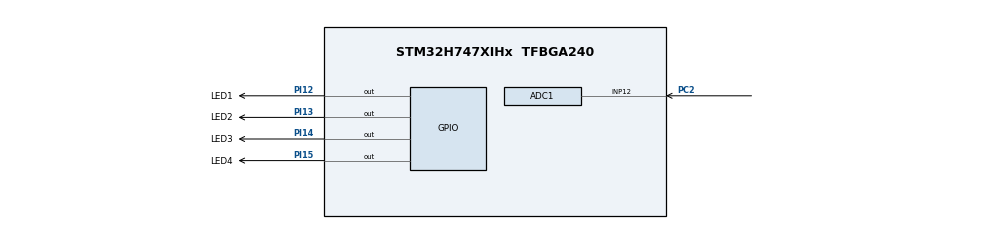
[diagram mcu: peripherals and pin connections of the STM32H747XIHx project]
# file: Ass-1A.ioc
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ADC1.Channel-1\#ChannelRegularConversion=ADC_CHANNEL_12
ADC1.ConversionDataManagement=ADC_CONVERSIONDATA_DMA_CIRCULAR
ADC1.ExternalTrigConv=ADC_EXTERNALTRIG_T3_TRGO
ADC1.NbrOfConversionFlag=1
ADC1.OffsetNumber-1\#ChannelRegularConversion=ADC_OFFSET_NONE
ADC1.OffsetSignedSaturation-1\#ChannelRegularConversion=DISABLE
ADC1.Overrun=ADC_OVR_DATA_OVERWRITTEN
ADC1.Rank-1\#ChannelRegularConversion=1
ADC1.Resolution=ADC_RESOLUTION_12B
ADC1.SamplingTime-1\#ChannelRegularConversion=ADC_SAMPLETIME_1CYCLE_5
ADC1.master=1
CortexM4.IPs=BDMA,DMA,FATFS_M4\:I,FREERTOS_M4\:I,IWDG2\:I,MDMA,NVIC2\:I,RCC,USB_DEVICE_M4\:I,USB_HOST_M4\:I,WWDG2\:I,USART1,USB_OTG_HS\:I,SPI2\:I,ADC3\:I,FMC\:I,QUADSPI\:I,SAI1\:I,ETH\:I,SPI5\:I,TIM8\:I,UART8\:I,DCMI\:I,RTC\:I,SDMMC1\:I,SPDIFRX1\:I,HDMI_CEC\:I,TIM13\:I,DEBUG,PDM2PCM_M4\:I,PWR,RESMGR_UTILITY,SYS_M4\:I,CORTEX_M4\:I,OPENAMP_M4\:I,VREFBUF,GPIO
CortexM7.IPs=BDMA\:I,DMA\:I,FATFS_M7\:I,FREERTOS_M7\:I,IWDG1\:I,MDMA\:I,NVIC1\:I,RCC\:I,USB_DEVICE_M7\:I,USB_HOST_M7\:I,WWDG1\:I,USART1\:I,CORTEX_M7\:I,DEBUG\:I,PDM2PCM_M7\:I,PWR\:I,RESMGR_UTILITY\:I,SYS\:I,OPENAMP_M7\:I,VREFBUF\:I,GPIO\:I,MEMORYMAP\:I,TIM3\:I,ADC1\:I
CortexM7.Pins=PI12,PI13,PI14,PI15
Dma.ADC1.0.Direction=DMA_PERIPH_TO_MEMORY
Dma.ADC1.0.EventEnable=DISABLE
Dma.ADC1.0.FIFOMode=DMA_FIFOMODE_DISABLE
Dma.ADC1.0.Instance=DMA1_Stream0
Dma.ADC1.0.MemDataAlignment=DMA_MDATAALIGN_HALFWORD
Dma.ADC1.0.MemInc=DMA_MINC_ENABLE
Dma.ADC1.0.Mode=DMA_CIRCULAR
Dma.ADC1.0.PeriphDataAlignment=DMA_PDATAALIGN_HALFWORD
Dma.ADC1.0.PeriphInc=DMA_PINC_DISABLE
Dma.ADC1.0.Polarity=HAL_DMAMUX_REQ_GEN_RISING
Dma.ADC1.0.Priority=DMA_PRIORITY_LOW
Dma.ADC1.0.RequestNumber=1
Dma.ADC1.0.SignalID=NONE
Dma.ADC1.0.SyncEnable=DISABLE
Dma.ADC1.0.SyncPolarity=HAL_DMAMUX_SYNC_NO_EVENT
Dma.ADC1.0.SyncRequestNumber=1
Dma.ADC1.0.SyncSignalID=NONE
Dma.Request0=ADC1
Mcu.Family=STM32H7
Mcu.Name=STM32H747XIHx
Mcu.Package=TFBGA240
NVIC1.ADC_IRQn=true\:0\:0\:false\:false\:true\:true\:true\:true
NVIC1.DMA1_Stream0_IRQn=true\:0\:0\:false\:false\:true\:false\:true\:true
NVIC1.PriorityGroup=NVIC_PRIORITYGROUP_4
NVIC1.TIM3_IRQn=true\:0\:0\:false\:false\:true\:true\:true\:true
NVIC2.PriorityGroup=NVIC_PRIORITYGROUP_4
PC2.PinAttribute=CortexM7
PC2.Signal=ADCx_INP12
PH0-OSC_IN\ (PH0).Mode=HSE-External-Oscillator
PH0-OSC_IN\ (PH0).PinAttribute=Free
PH0-OSC_IN\ (PH0).Signal=RCC_OSC_IN
PH1-OSC_OUT\ (PH1).Mode=HSE-External-Oscillator
PH1-OSC_OUT\ (PH1).PinAttribute=Free
PH1-OSC_OUT\ (PH1).Signal=RCC_OSC_OUT
PI12.GPIO_Label=LED1
PI12.PinAttribute=CortexM7
PI12.Signal=GPIO_Output
PI13.GPIO_Label=LED2
PI13.PinAttribute=CortexM7
PI13.Signal=GPIO_Output
PI14.GPIO_Label=LED3
PI14.PinAttribute=CortexM7
PI14.Signal=GPIO_Output
PI15.GPIO_Label=LED4
PI15.PinAttribute=CortexM7
PI15.Signal=GPIO_Output
ProjectManager.HeapSize=M4-0x200,M7-0x200
ProjectManager.StackSize=M4-0x400,M7-0x400
ProjectManager.TargetToolchain=STM32CubeIDE
RCC.ADCFreq_Value=75000000
RCC.APB1Freq_Value=100000000
RCC.APB2Freq_Value=100000000
RCC.APB3Freq_Value=100000000
RCC.APB4Freq_Value=100000000
RCC.CortexFreq_Value=400000000
RCC.D1PPRE=RCC_APB3_DIV2
RCC.D2PPRE1=RCC_APB1_DIV2
RCC.D2PPRE2=RCC_APB2_DIV2
RCC.D3PPRE=RCC_APB4_DIV2
RCC.DIVM1=5
RCC.DIVM2=2
RCC.DIVN1=160
RCC.DIVN2=12
RCC.DIVQ1=5
RCC.HCLKFreq_Value=200000000
RCC.HPRE=RCC_HCLK_DIV2
RCC.PLL2FRACN=0
RCC.PLL3FRACN=0
RCC.PLLFRACN=0
RCC.PLLSourceVirtual=RCC_PLLSOURCE_HSE
RCC.PWR_Regulator_Voltage_Scale=PWR_REGULATOR_VOLTAGE_SCALE1
RCC.SYSCLKFreq_VALUE=400000000
RCC.SYSCLKSource=RCC_SYSCLKSOURCE_PLLCLK
RCC.SupplySource=PWR_DIRECT_SMPS_SUPPLY
RCC.USBFreq_Value=160000000
SH.ADCx_INP12.0=ADC1_INP12,IN12-Single-Ended
TIM3.AutoReloadPreload=TIM_AUTORELOAD_PRELOAD_DISABLE
TIM3.Period=4999
TIM3.Prescaler=9999
TIM3.TIM_MasterOutputTrigger=TIM_TRGO_UPDATE
VP_MEMORYMAP_VS_MEMORYMAP.Mode=CurAppReg
VP_SYS_M4_VS_Systick.Mode=SysTick
VP_TIM3_VS_ClockSourceINT.Mode=Internal
board=STM32H747I-DISCO

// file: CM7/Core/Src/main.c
/* USER CODE BEGIN Header */
/**
  ******************************************************************************
  * @file           : main.c
  * @brief          : Main program body
  ******************************************************************************
  * @attention
  *
  * Copyright (c) 2025 STMicroelectronics.
  * All rights reserved.
  *
  * This software is licensed under terms that can be found in the LICENSE file
  * in the root directory of this software component.
  * If no LICENSE file comes with this software, it is provided AS-IS.
  *
  ******************************************************************************
  */
/* USER CODE END Header */
#include "main.h"

/* USER CODE BEGIN Includes */
#include "Ass-1A.h"
/* USER CODE END Includes */

/* USER CODE BEGIN PD */

#ifndef HSEM_ID_0
#define HSEM_ID_0 (0U) /* HW semaphore 0*/
#endif

/* USER CODE END PD */

ADC_HandleTypeDef hadc1;
DMA_HandleTypeDef hdma_adc1;

TIM_HandleTypeDef htim3;

void SystemClock_Config(void);
static void MX_GPIO_Init(void);
static void MX_DMA_Init(void);
static void MX_TIM3_Init(void);
static void MX_ADC1_Init(void);
/* USER CODE BEGIN PFP */
extern void initialise_monitor_handles(void);
/* USER CODE END PFP */

int main(void)
{

  /* USER CODE BEGIN 1 */
 	initialise_monitor_handles();
  /* USER CODE END 1 */
/* USER CODE BEGIN Boot_Mode_Sequence_0 */
//  int32_t timeout;
/* USER CODE END Boot_Mode_Sequence_0 */

/* USER CODE BEGIN Boot_Mode_Sequence_1 */
  /* Wait until CPU2 boots and enters in stop mode or timeout*/
/*
	timeout = 0xFFFF;
  while((__HAL_RCC_GET_FLAG(RCC_FLAG_D2CKRDY) != RESET) && (timeout-- > 0));
  if ( timeout < 0 )
  {
  Error_Handler();
  }
 */
/* USER CODE END Boot_Mode_Sequence_1 */
  /* MCU Configuration--------------------------------------------------------*/

  /* Reset of all peripherals, Initializes the Flash interface and the Systick. */
  HAL_Init();

  /* Configure the system clock */
  SystemClock_Config();
/* USER CODE BEGIN Boot_Mode_Sequence_2 */
/* When system initialization is finished, Cortex-M7 will release Cortex-M4 by means of
HSEM notification */
/*HW semaphore Clock enable*/
//__HAL_RCC_HSEM_CLK_ENABLE();
/*Take HSEM */
//HAL_HSEM_FastTake(HSEM_ID_0);
/*Release HSEM in order to notify the CPU2(CM4)*/
//HAL_HSEM_Release(HSEM_ID_0,0);
/* wait until CPU2 wakes up from stop mode */
//timeout = 0xFFFF;
//while((__HAL_RCC_GET_FLAG(RCC_FLAG_D2CKRDY) == RESET) && (timeout-- > 0));
//if ( timeout < 0 )
//{
//Error_Handler();
//}
/* USER CODE END Boot_Mode_Sequence_2 */

  /* Initialize all configured peripherals */
  MX_GPIO_Init();
  MX_DMA_Init();
  MX_TIM3_Init();
  MX_ADC1_Init();
  /* USER CODE BEGIN 2 */
  // Start with LED off
	HAL_GPIO_WritePin (GPIOI, LED1_Pin,1);
	HAL_GPIO_WritePin (GPIOI, LED2_Pin,1);
	HAL_GPIO_WritePin (GPIOI, LED3_Pin,1);
	HAL_GPIO_WritePin (GPIOI, LED4_Pin,1);

  // Call the user code (never returns)
  Ass_1A_main();

  /* USER CODE END 2 */

  /* Infinite loop */
  while (1)
  {

  }
}

void SystemClock_Config(void)
{
  RCC_OscInitTypeDef RCC_OscInitStruct = {0};
  RCC_ClkInitTypeDef RCC_ClkInitStruct = {0};

  /** Supply configuration update enable
  */
  HAL_PWREx_ConfigSupply(PWR_DIRECT_SMPS_SUPPLY);

  /** Configure the main internal regulator output voltage
  */
  __HAL_PWR_VOLTAGESCALING_CONFIG(PWR_REGULATOR_VOLTAGE_SCALE1);

  while(!__HAL_PWR_GET_FLAG(PWR_FLAG_VOSRDY)) {}

  /** Initializes the RCC Oscillators according to the specified parameters
  * in the RCC_OscInitTypeDef structure.
  */
  RCC_OscInitStruct.OscillatorType = RCC_OSCILLATORTYPE_HSE;
  RCC_OscInitStruct.HSEState = RCC_HSE_ON;
  RCC_OscInitStruct.PLL.PLLState = RCC_PLL_ON;
  RCC_OscInitStruct.PLL.PLLSource = RCC_PLLSOURCE_HSE;
  RCC_OscInitStruct.PLL.PLLM = 5;
  RCC_OscInitStruct.PLL.PLLN = 160;
  RCC_OscInitStruct.PLL.PLLP = 2;
  RCC_OscInitStruct.PLL.PLLQ = 5;
  RCC_OscInitStruct.PLL.PLLR = 2;
  RCC_OscInitStruct.PLL.PLLRGE = RCC_PLL1VCIRANGE_2;
  RCC_OscInitStruct.PLL.PLLVCOSEL = RCC_PLL1VCOWIDE;
  RCC_OscInitStruct.PLL.PLLFRACN = 0;
  if (HAL_RCC_OscConfig(&RCC_OscInitStruct) != HAL_OK)
  {
    Error_Handler();
  }

  /** Initializes the CPU, AHB and APB buses clocks
  */
  RCC_ClkInitStruct.ClockType = RCC_CLOCKTYPE_HCLK|RCC_CLOCKTYPE_SYSCLK
                              |RCC_CLOCKTYPE_PCLK1|RCC_CLOCKTYPE_PCLK2
                              |RCC_CLOCKTYPE_D3PCLK1|RCC_CLOCKTYPE_D1PCLK1;
  RCC_ClkInitStruct.SYSCLKSource = RCC_SYSCLKSOURCE_PLLCLK;
  RCC_ClkInitStruct.SYSCLKDivider = RCC_SYSCLK_DIV1;
  RCC_ClkInitStruct.AHBCLKDivider = RCC_HCLK_DIV2;
  RCC_ClkInitStruct.APB3CLKDivider = RCC_APB3_DIV2;
  RCC_ClkInitStruct.APB1CLKDivider = RCC_APB1_DIV2;
  RCC_ClkInitStruct.APB2CLKDivider = RCC_APB2_DIV2;
  RCC_ClkInitStruct.APB4CLKDivider = RCC_APB4_DIV2;

  if (HAL_RCC_ClockConfig(&RCC_ClkInitStruct, FLASH_LATENCY_2) != HAL_OK)
  {
    Error_Handler();
  }
}

static void MX_ADC1_Init(void)
{

  ADC_MultiModeTypeDef multimode = {0};
  ADC_ChannelConfTypeDef sConfig = {0};

  /** Common config
  */
  hadc1.Instance = ADC1;
  hadc1.Init.ClockPrescaler = ADC_CLOCK_ASYNC_DIV1;
  hadc1.Init.Resolution = ADC_RESOLUTION_12B;
  hadc1.Init.ScanConvMode = ADC_SCAN_DISABLE;
  hadc1.Init.EOCSelection = ADC_EOC_SINGLE_CONV;
  hadc1.Init.LowPowerAutoWait = DISABLE;
  hadc1.Init.ContinuousConvMode = DISABLE;
  hadc1.Init.NbrOfConversion = 1;
  hadc1.Init.DiscontinuousConvMode = DISABLE;
  hadc1.Init.ExternalTrigConv = ADC_EXTERNALTRIG_T3_TRGO;
  hadc1.Init.ExternalTrigConvEdge = ADC_EXTERNALTRIGCONVEDGE_RISING;
  hadc1.Init.ConversionDataManagement = ADC_CONVERSIONDATA_DMA_CIRCULAR;
  hadc1.Init.Overrun = ADC_OVR_DATA_OVERWRITTEN;
  hadc1.Init.LeftBitShift = ADC_LEFTBITSHIFT_NONE;
  hadc1.Init.OversamplingMode = DISABLE;
  hadc1.Init.Oversampling.Ratio = 1;
  if (HAL_ADC_Init(&hadc1) != HAL_OK)
  {
    Error_Handler();
  }

  /** Configure the ADC multi-mode
  */
  multimode.Mode = ADC_MODE_INDEPENDENT;
  if (HAL_ADCEx_MultiModeConfigChannel(&hadc1, &multimode) != HAL_OK)
  {
    Error_Handler();
  }

  /** Configure Regular Channel
  */
  sConfig.Channel = ADC_CHANNEL_12;
  sConfig.Rank = ADC_REGULAR_RANK_1;
  sConfig.SamplingTime = ADC_SAMPLETIME_1CYCLE_5;
  sConfig.SingleDiff = ADC_SINGLE_ENDED;
  sConfig.OffsetNumber = ADC_OFFSET_NONE;
  sConfig.Offset = 0;
  sConfig.OffsetSignedSaturation = DISABLE;
  if (HAL_ADC_ConfigChannel(&hadc1, &sConfig) != HAL_OK)
  {
    Error_Handler();
  }

}

static void MX_TIM3_Init(void)
{

  TIM_ClockConfigTypeDef sClockSourceConfig = {0};
  TIM_MasterConfigTypeDef sMasterConfig = {0};

  htim3.Instance = TIM3;
  htim3.Init.Prescaler = 9999;
  htim3.Init.CounterMode = TIM_COUNTERMODE_UP;
  htim3.Init.Period = 4999;
  htim3.Init.ClockDivision = TIM_CLOCKDIVISION_DIV1;
  htim3.Init.AutoReloadPreload = TIM_AUTORELOAD_PRELOAD_DISABLE;
  if (HAL_TIM_Base_Init(&htim3) != HAL_OK)
  {
    Error_Handler();
  }
  sClockSourceConfig.ClockSource = TIM_CLOCKSOURCE_INTERNAL;
  if (HAL_TIM_ConfigClockSource(&htim3, &sClockSourceConfig) != HAL_OK)
  {
    Error_Handler();
  }
  sMasterConfig.MasterOutputTrigger = TIM_TRGO_UPDATE;
  sMasterConfig.MasterSlaveMode = TIM_MASTERSLAVEMODE_DISABLE;
  if (HAL_TIMEx_MasterConfigSynchronization(&htim3, &sMasterConfig) != HAL_OK)
  {
    Error_Handler();
  }

}

static void MX_DMA_Init(void)
{

  /* DMA controller clock enable */
  __HAL_RCC_DMA1_CLK_ENABLE();

  /* DMA interrupt init */
  /* DMA1_Stream0_IRQn interrupt configuration */
  HAL_NVIC_SetPriority(DMA1_Stream0_IRQn, 0, 0);
  HAL_NVIC_EnableIRQ(DMA1_Stream0_IRQn);

}

static void MX_GPIO_Init(void)
{
  GPIO_InitTypeDef GPIO_InitStruct = {0};

  /* GPIO Ports Clock Enable */
  __HAL_RCC_GPIOI_CLK_ENABLE();
  __HAL_RCC_GPIOC_CLK_ENABLE();

  /*Configure GPIO pin Output Level */
  HAL_GPIO_WritePin(GPIOI, LED1_Pin|LED2_Pin|LED3_Pin|LED4_Pin, GPIO_PIN_RESET);

  /*Configure GPIO pins : LED1_Pin LED2_Pin LED3_Pin LED4_Pin */
  GPIO_InitStruct.Pin = LED1_Pin|LED2_Pin|LED3_Pin|LED4_Pin;
  GPIO_InitStruct.Mode = GPIO_MODE_OUTPUT_PP;
  GPIO_InitStruct.Pull = GPIO_NOPULL;
  GPIO_InitStruct.Speed = GPIO_SPEED_FREQ_LOW;
  HAL_GPIO_Init(GPIOI, &GPIO_InitStruct);

}

void Error_Handler(void)
{
  __disable_irq();
  while (1)
  {
  }
}
